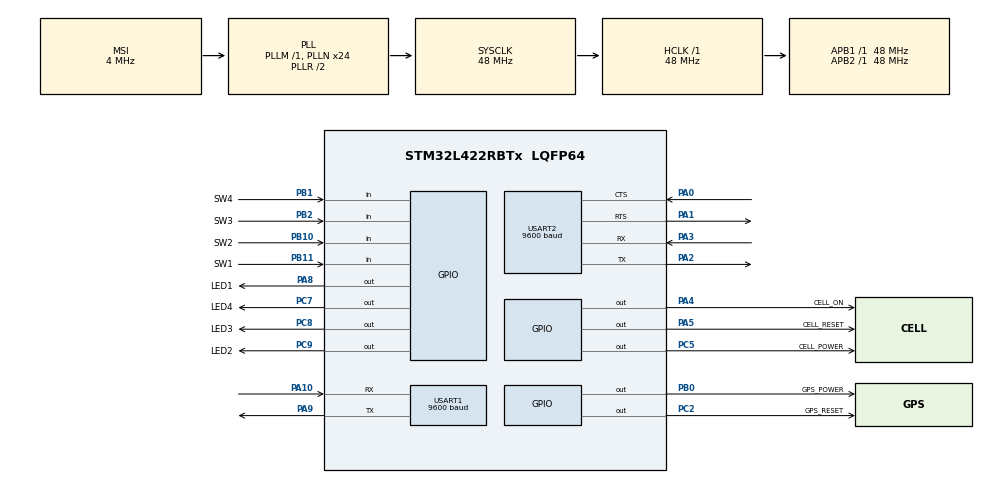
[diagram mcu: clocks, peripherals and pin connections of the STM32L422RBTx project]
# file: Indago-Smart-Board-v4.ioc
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Mcu.Family=STM32L4
Mcu.Name=STM32L422RBTx
Mcu.Package=LQFP64
NVIC.PriorityGroup=NVIC_PRIORITYGROUP_4
PA0.Mode=CTS_RTS
PA0.Signal=USART2_CTS
PA1.Mode=CTS_RTS
PA1.Signal=USART2_RTS
PA10.Mode=Asynchronous
PA10.Signal=USART1_RX
PA2.Mode=Asynchronous
PA2.Signal=USART2_TX
PA3.Mode=Asynchronous
PA3.Signal=USART2_RX
PA4.GPIO_Label=CELL_ON
PA4.Signal=GPIO_Output
PA5.GPIO_Label=CELL_RESET
PA5.Signal=GPIO_Output
PA8.GPIO_Label=LED1
PA8.Signal=GPIO_Output
PA9.Mode=Asynchronous
PA9.Signal=USART1_TX
PB0.GPIO_Label=GPS_POWER
PB0.Signal=GPIO_Output
PB1.GPIO_Label=SW4
PB1.GPIO_PuPd=GPIO_PULLUP
PB1.Signal=GPIO_Input
PB10.GPIO_Label=SW2
PB10.GPIO_PuPd=GPIO_PULLUP
PB10.Signal=GPIO_Input
PB11.GPIO_Label=SW1
PB11.GPIO_PuPd=GPIO_PULLUP
PB11.Signal=GPIO_Input
PB2.GPIO_Label=SW3
PB2.GPIO_PuPd=GPIO_PULLUP
PB2.Signal=GPIO_Input
PC2.GPIO_Label=GPS_RESET
PC2.Signal=GPIO_Output
PC5.GPIO_Label=CELL_POWER
PC5.Signal=GPIO_Output
PC7.GPIO_Label=LED4
PC7.Signal=GPIO_Output
PC8.GPIO_Label=LED3
PC8.Signal=GPIO_Output
PC9.GPIO_Label=LED2
PC9.Signal=GPIO_Output
ProjectManager.HeapSize=0x200
ProjectManager.StackSize=0x400
ProjectManager.TargetToolchain=MDK-ARM V5.27
RCC.ADCFreq_Value=48000000
RCC.AHBFreq_Value=48000000
RCC.APB1Freq_Value=48000000
RCC.APB1TimFreq_Value=48000000
RCC.APB2Freq_Value=48000000
RCC.APB2TimFreq_Value=48000000
RCC.CortexFreq_Value=48000000
RCC.HCLKFreq_Value=48000000
RCC.HSE_VALUE=8000000
RCC.HSI48_VALUE=48000000
RCC.HSI_VALUE=16000000
RCC.LSE_VALUE=32768
RCC.MSI_VALUE=4000000
RCC.PLLN=24
RCC.SYSCLKFreq_VALUE=48000000
RCC.SYSCLKSource=RCC_SYSCLKSOURCE_PLLCLK
RCC.USART1CLockSelection=RCC_USART1CLKSOURCE_HSI
RCC.USART2CLockSelection=RCC_USART2CLKSOURCE_HSI
RCC.USBFreq_Value=4000000
RCC.VCOOutputFreq_Value=96000000
USART1.BaudRate=9600
USART1.VirtualMode-Asynchronous=VM_ASYNC
USART2.BaudRate=9600
USART2.VirtualMode-Asynchronous=VM_ASYNC
board=custom

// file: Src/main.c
/**
  ******************************************************************************
  * @file           : main.c
  * @brief          : Main program body
  ******************************************************************************
  */

#include <stdio.h>

#include "main.h"
#include "ublox_gps.h"
#include "ublox_r4.h"
#include "print.h"

#include "MQTTPacket.h"

UART_HandleTypeDef huart1; //MAX-8Q
UART_HandleTypeDef huart2; //SARA-R4

void SystemClock_Config(void);
static void MX_GPIO_Init(void);
static void MX_USART1_UART_Init(void);
static void MX_USART2_UART_Init(void);

extern uint32_t __stack_chk_guard = 0xEE;

__interwork __nounwind __noreturn void __stack_chk_fail(void){
  while(1)
    ;
}

int main(void)
{
  /* MCU Configuration--------------------------------------------------------*/
  //json_t *root;

  /* Reset of all peripherals, Initializes the Flash interface and the Systick. */
  HAL_Init();

  /* Configure the system clock */
  SystemClock_Config();

  /* Initialize all configured peripherals */
  MX_GPIO_Init();
  MX_USART1_UART_Init();
  MX_USART2_UART_Init();
  //SET_BIT(huart1.Instance->CR3, USART_CR3_EIE);                                 // Turn on RNE IRQ (Main UART IRQ)
  //SET_BIT(huart1.Instance->CR1, USART_CR1_RXNEIE);
  printf("Testing");

  for(uint8_t i = 0; i < 4; i++){
    HAL_GPIO_TogglePin(LED4_GPIO_Port, LED4_Pin);
    HAL_Delay(250);
  }

  // PA1     ------> USART2_RTS
  /*GPIO_InitTypeDef GPIO_InitStruct = {0};
  GPIO_InitStruct.Pin = GPIO_PIN_1;
  GPIO_InitStruct.Mode = GPIO_MODE_OUTPUT_PP;
  GPIO_InitStruct.Pull = GPIO_NOPULL;
  GPIO_InitStruct.Speed = GPIO_SPEED_FREQ_VERY_HIGH;
  HAL_GPIO_Init(GPIOA, &GPIO_InitStruct);
  HAL_GPIO_WritePin(GPIOA, GPIO_PIN_1, GPIO_PIN_RESET);

  SARA_R4_HW_Power_On();
  HAL_Delay(5000);

  //UBX_GPS_Init(&huart1);
  SARA_R4_Init(&huart2);

  Infinite loop */
  while (1)
  {
  }
}

void SystemClock_Config(void)
{
  RCC_OscInitTypeDef RCC_OscInitStruct = {0};
  RCC_ClkInitTypeDef RCC_ClkInitStruct = {0};
  RCC_PeriphCLKInitTypeDef PeriphClkInit = {0};

  /** Configure the main internal regulator output voltage
  */
  if (HAL_PWREx_ControlVoltageScaling(PWR_REGULATOR_VOLTAGE_SCALE1) != HAL_OK)
  {
    Error_Handler();
  }
  /** Initializes the CPU, AHB and APB busses clocks
  */
  RCC_OscInitStruct.OscillatorType = RCC_OSCILLATORTYPE_HSI|RCC_OSCILLATORTYPE_MSI;
  RCC_OscInitStruct.HSIState = RCC_HSI_ON;
  RCC_OscInitStruct.HSICalibrationValue = RCC_HSICALIBRATION_DEFAULT;
  RCC_OscInitStruct.MSIState = RCC_MSI_ON;
  RCC_OscInitStruct.MSICalibrationValue = 0;
  RCC_OscInitStruct.MSIClockRange = RCC_MSIRANGE_6;
  RCC_OscInitStruct.PLL.PLLState = RCC_PLL_ON;
  RCC_OscInitStruct.PLL.PLLSource = RCC_PLLSOURCE_MSI;
  RCC_OscInitStruct.PLL.PLLM = 1;
  RCC_OscInitStruct.PLL.PLLN = 24;
  RCC_OscInitStruct.PLL.PLLQ = RCC_PLLQ_DIV2;
  RCC_OscInitStruct.PLL.PLLR = RCC_PLLR_DIV2;
  if (HAL_RCC_OscConfig(&RCC_OscInitStruct) != HAL_OK)
  {
    Error_Handler();
  }
  /** Initializes the CPU, AHB and APB busses clocks
  */
  RCC_ClkInitStruct.ClockType = RCC_CLOCKTYPE_HCLK|RCC_CLOCKTYPE_SYSCLK
                              |RCC_CLOCKTYPE_PCLK1|RCC_CLOCKTYPE_PCLK2;
  RCC_ClkInitStruct.SYSCLKSource = RCC_SYSCLKSOURCE_PLLCLK;
  RCC_ClkInitStruct.AHBCLKDivider = RCC_SYSCLK_DIV1;
  RCC_ClkInitStruct.APB1CLKDivider = RCC_HCLK_DIV1;
  RCC_ClkInitStruct.APB2CLKDivider = RCC_HCLK_DIV1;

  if (HAL_RCC_ClockConfig(&RCC_ClkInitStruct, FLASH_LATENCY_2) != HAL_OK)
  {
    Error_Handler();
  }
  PeriphClkInit.PeriphClockSelection = RCC_PERIPHCLK_USART1|RCC_PERIPHCLK_USART2;
  PeriphClkInit.Usart1ClockSelection = RCC_USART1CLKSOURCE_HSI;
  PeriphClkInit.Usart2ClockSelection = RCC_USART2CLKSOURCE_HSI;
  if (HAL_RCCEx_PeriphCLKConfig(&PeriphClkInit) != HAL_OK)
  {
    Error_Handler();
  }
}

static void MX_USART1_UART_Init(void)
{
  huart1.Instance = USART1;
  huart1.Init.BaudRate = 115200;
  huart1.Init.WordLength = UART_WORDLENGTH_8B;
  huart1.Init.StopBits = UART_STOPBITS_1;
  huart1.Init.Parity = UART_PARITY_NONE;
  huart1.Init.Mode = UART_MODE_TX_RX;
  huart1.Init.HwFlowCtl = UART_HWCONTROL_NONE;
  huart1.Init.OverSampling = UART_OVERSAMPLING_16;
  huart1.Init.OneBitSampling = UART_ONE_BIT_SAMPLE_DISABLE;
  huart1.AdvancedInit.AdvFeatureInit = UART_ADVFEATURE_NO_INIT;
  if (HAL_UART_Init(&huart1) != HAL_OK)
  {
    Error_Handler();
  }
}

static void MX_USART2_UART_Init(void)
{
  huart2.Instance = USART2;
  huart2.Init.BaudRate = 115200;
  huart2.Init.WordLength = UART_WORDLENGTH_8B;
  huart2.Init.StopBits = UART_STOPBITS_1;
  huart2.Init.Parity = UART_PARITY_NONE;
  huart2.Init.Mode = UART_MODE_TX_RX;
  huart2.Init.HwFlowCtl = UART_HWCONTROL_RTS_CTS;
  huart2.Init.OverSampling = UART_OVERSAMPLING_16;
  huart2.Init.OneBitSampling = UART_ONE_BIT_SAMPLE_DISABLE;
  huart2.AdvancedInit.AdvFeatureInit = UART_ADVFEATURE_NO_INIT;
  if (HAL_UART_Init(&huart2) != HAL_OK)
  {
    Error_Handler();
  }

}

static void MX_GPIO_Init(void)
{
  GPIO_InitTypeDef GPIO_InitStruct = {0};

  /* GPIO Ports Clock Enable */
  __HAL_RCC_GPIOC_CLK_ENABLE();
  __HAL_RCC_GPIOA_CLK_ENABLE();
  __HAL_RCC_GPIOB_CLK_ENABLE();

  /*Configure GPIO pin Output Level */
  HAL_GPIO_WritePin(GPIOC, LED4_Pin|LED3_Pin
                          |LED2_Pin, GPIO_PIN_RESET);
  HAL_GPIO_WritePin(GPIOC, GPS_RESET_Pin|CELL_POWER_Pin, GPIO_PIN_SET);

  /*Configure GPIO pin Output Level */
  HAL_GPIO_WritePin(GPIOA, LED1_Pin, GPIO_PIN_RESET);
  HAL_GPIO_WritePin(GPIOA, CELL_RESET_Pin|CELL_ON_Pin, GPIO_PIN_SET);

  /*Configure GPIO pin Output Level */
  HAL_GPIO_WritePin(GPS_POWER_GPIO_Port, GPS_POWER_Pin, GPIO_PIN_SET);

  HAL_GPIO_WritePin(LORA_RESET_GPIO_Port, LORA_RESET_Pin, GPIO_PIN_RESET);

  /*Configure GPIO pins : GPS_RESET_Pin CELL_POWER_Pin LED4_Pin LED3_Pin LED2_Pin */
  GPIO_InitStruct.Pin = GPS_RESET_Pin|CELL_POWER_Pin|LED4_Pin|LED3_Pin|LED2_Pin;
  GPIO_InitStruct.Mode = GPIO_MODE_OUTPUT_PP;
  GPIO_InitStruct.Pull = GPIO_NOPULL;
  GPIO_InitStruct.Speed = GPIO_SPEED_FREQ_LOW;
  HAL_GPIO_Init(GPIOC, &GPIO_InitStruct);

  /*Configure GPIO pins : LED1_Pin */
  GPIO_InitStruct.Pin = LED1_Pin;
  GPIO_InitStruct.Mode = GPIO_MODE_OUTPUT_PP;
  GPIO_InitStruct.Pull = GPIO_NOPULL;
  GPIO_InitStruct.Speed = GPIO_SPEED_FREQ_LOW;
  HAL_GPIO_Init(GPIOA, &GPIO_InitStruct);

  /*Configure GPIO pins : LORA_RESET_Pin */
  GPIO_InitStruct.Pin = LORA_RESET_Pin;
  GPIO_InitStruct.Mode = GPIO_MODE_OUTPUT_PP;
  GPIO_InitStruct.Pull = GPIO_NOPULL;
  GPIO_InitStruct.Speed = GPIO_SPEED_FREQ_HIGH;
  HAL_GPIO_Init(GPIOB, &GPIO_InitStruct);

  /*Configure GPIO pins : CELL_ON_Pin | CELL_RESET_Pin */
  GPIO_InitStruct.Pin = CELL_ON_Pin;
  GPIO_InitStruct.Mode = GPIO_MODE_OUTPUT_OD;
  GPIO_InitStruct.Pull = GPIO_NOPULL;
  GPIO_InitStruct.Speed = GPIO_SPEED_FREQ_LOW;
  HAL_GPIO_Init(GPIOA, &GPIO_InitStruct);

  /*Configure GPIO pin : GPS_POWER_Pin */
  GPIO_InitStruct.Pin = GPS_POWER_Pin;
  GPIO_InitStruct.Mode = GPIO_MODE_OUTPUT_PP;
  GPIO_InitStruct.Pull = GPIO_NOPULL;
  GPIO_InitStruct.Speed = GPIO_SPEED_FREQ_LOW;
  HAL_GPIO_Init(GPS_POWER_GPIO_Port, &GPIO_InitStruct);

  /*Configure GPIO pins : SW4_Pin SW3_Pin SW2_Pin SW1_Pin */
  GPIO_InitStruct.Pin = SW4_Pin|SW3_Pin|SW2_Pin|SW1_Pin;
  GPIO_InitStruct.Mode = GPIO_MODE_INPUT;
  GPIO_InitStruct.Pull = GPIO_PULLUP;
  HAL_GPIO_Init(GPIOB, &GPIO_InitStruct);

}

void debugPrintln(char _out[]){
  HAL_UART_Transmit(&huart1, (uint8_t *) _out, strlen(_out), 10);
  char newline[2] = "\r\n";
  HAL_UART_Transmit(&huart1, (uint8_t *) newline, 2, 10);
}

void Error_Handler(void)
{
  /* USER CODE BEGIN Error_Handler_Debug */
  /* User can add his own implementation to report the HAL error return state */
  while(1)
    ;
  /* USER CODE END Error_Handler_Debug */
}

/************************ (C) COPYRIGHT STMicroelectronics *****END OF FILE****/
